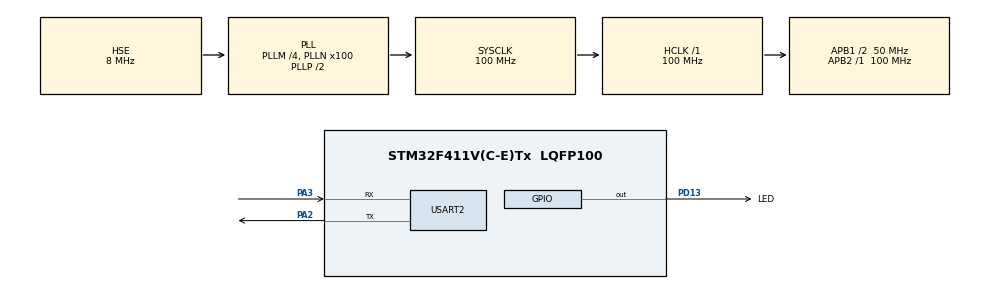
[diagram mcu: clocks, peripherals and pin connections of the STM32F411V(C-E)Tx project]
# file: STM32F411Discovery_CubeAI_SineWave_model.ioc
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Mcu.Family=STM32F4
Mcu.Name=STM32F411V(C-E)Tx
Mcu.Package=LQFP100
NVIC.PriorityGroup=NVIC_PRIORITYGROUP_4
PA13.Mode=Trace_Asynchronous_SW
PA13.Signal=SYS_JTMS-SWDIO
PA14.Mode=Trace_Asynchronous_SW
PA14.Signal=SYS_JTCK-SWCLK
PA2.Mode=Asynchronous
PA2.Signal=USART2_TX
PA3.Mode=Asynchronous
PA3.Signal=USART2_RX
PB3.Mode=Trace_Asynchronous_SW
PB3.Signal=SYS_JTDO-SWO
PD13.GPIO_Label=LED
PD13.Signal=GPIO_Output
PH0\ -\ OSC_IN.Mode=HSE-External-Oscillator
PH0\ -\ OSC_IN.Signal=RCC_OSC_IN
PH1\ -\ OSC_OUT.Mode=HSE-External-Oscillator
PH1\ -\ OSC_OUT.Signal=RCC_OSC_OUT
ProjectManager.HeapSize=0x200
ProjectManager.StackSize=0x400
ProjectManager.TargetToolchain=STM32CubeIDE
RCC.48MHZClocksFreq_Value=50000000
RCC.AHBFreq_Value=100000000
RCC.APB1CLKDivider=RCC_HCLK_DIV2
RCC.APB1Freq_Value=50000000
RCC.APB1TimFreq_Value=100000000
RCC.APB2Freq_Value=100000000
RCC.APB2TimFreq_Value=100000000
RCC.CortexFreq_Value=100000000
RCC.HCLKFreq_Value=100000000
RCC.HSE_VALUE=8000000
RCC.HSI_VALUE=16000000
RCC.LSE_VALUE=32768
RCC.PLLM=4
RCC.PLLN=100
RCC.PLLSourceVirtual=RCC_PLLSOURCE_HSE
RCC.SYSCLKFreq_VALUE=100000000
RCC.SYSCLKSource=RCC_SYSCLKSOURCE_PLLCLK
RCC.VCOOutputFreq_Value=200000000
STMicroelectronics.X-CUBE-AI.9.0.0.ActivationBufferSizeList=128
STMicroelectronics.X-CUBE-AI.9.0.0.ActivationBuffers=pool0
STMicroelectronics.X-CUBE-AI.9.0.0.ActivationNames=pool0
STMicroelectronics.X-CUBE-AI.9.0.0.ActivationSizes=AI_MYSINE_MODEL_DATA_ACTIVATION_1_SIZE
STMicroelectronics.X-CUBE-AI.9.0.0.HeapSize=0x800
STMicroelectronics.X-CUBE-AI.9.0.0.InternalRamActivationBufferMaxSize=AI_MYSINE_MODEL_DATA_ACTIVATIONS_SIZE
STMicroelectronics.X-CUBE-AI.9.0.0.LatestDirectoryUsed-0397be3772422ef14a2fe8161df3de680c5d4849b99f2a567ee8d7afe09b7841=C\:\\Users\\Bazar\\Desktop\\New folder
STMicroelectronics.X-CUBE-AI.9.0.0.MaximumNumberOfInputLayer=1
STMicroelectronics.X-CUBE-AI.9.0.0.MaximumNumberOfOutputLayer=1
STMicroelectronics.X-CUBE-AI.9.0.0.MaximumSizeOfInputLayer=1
STMicroelectronics.X-CUBE-AI.9.0.0.MaximumSizeOfOutputLayer=1
STMicroelectronics.X-CUBE-AI.9.0.0.ModelActualCompression-0397be3772422ef14a2fe8161df3de680c5d4849b99f2a567ee8d7afe09b7841=0.0
STMicroelectronics.X-CUBE-AI.9.0.0.ModelCompression-0397be3772422ef14a2fe8161df3de680c5d4849b99f2a567ee8d7afe09b7841=None
STMicroelectronics.X-CUBE-AI.9.0.0.ModelFlashOccupation-0397be3772422ef14a2fe8161df3de680c5d4849b99f2a567ee8d7afe09b7841=1284
STMicroelectronics.X-CUBE-AI.9.0.0.ModelHashList=0397be3772422ef14a2fe8161df3de680c5d4849b99f2a567ee8d7afe09b7841
STMicroelectronics.X-CUBE-AI.9.0.0.ModelKind-0397be3772422ef14a2fe8161df3de680c5d4849b99f2a567ee8d7afe09b7841=TFLITE
STMicroelectronics.X-CUBE-AI.9.0.0.ModelMacc-0397be3772422ef14a2fe8161df3de680c5d4849b99f2a567ee8d7afe09b7841=353
STMicroelectronics.X-CUBE-AI.9.0.0.ModelName-0397be3772422ef14a2fe8161df3de680c5d4849b99f2a567ee8d7afe09b7841=mysine_model
STMicroelectronics.X-CUBE-AI.9.0.0.ModelNameList=mysine_model
STMicroelectronics.X-CUBE-AI.9.0.0.ModelRamOccupation-0397be3772422ef14a2fe8161df3de680c5d4849b99f2a567ee8d7afe09b7841=128
STMicroelectronics.X-CUBE-AI.9.0.0.ModelStructureFile-0397be3772422ef14a2fe8161df3de680c5d4849b99f2a567ee8d7afe09b7841=C\:\\Users\\Bazar\\Desktop\\New folder\\sine_model.tflite
STMicroelectronics.X-CUBE-AI.9.0.0.ModelType-0397be3772422ef14a2fe8161df3de680c5d4849b99f2a567ee8d7afe09b7841=STM32Cube.AI MCU runtime
STMicroelectronics.X-CUBE-AI.9.0.0.ReadyForCodeGeneration=true
STMicroelectronics.X-CUBE-AI.9.0.0.StackSize=0x800
STMicroelectronics.X-CUBE-AI.9.0.0.WorkingBufferStartAddrList=0xFFFFFFFF
STMicroelectronics.X-CUBE-AI.9.0.0.XAaCUBEAaAICcArtificialOoIntelligenceJjCore=true
STMicroelectronics.X-CUBE-AI.9.0.0.copyWeightToRam=false
STMicroelectronics.X-CUBE-AI.9.0.0.customLayerConfigEnabled=false
STMicroelectronics.X-CUBE-AI.9.0.0.noOnnxIoTranspose=false
STMicroelectronics.X-CUBE-AI.9.0.0.useInputAllocation=true
STMicroelectronics.X-CUBE-AI.9.0.0.useOutputAllocation=true
USART2.VirtualMode=VM_ASYNC
VP_CRC_VS_CRC.Mode=CRC_Activate
VP_STMicroelectronics.X-CUBE-AI_VS_ArtificialOoIntelligenceJjXAaCUBEAaAI_9.0.0.Mode=ArtificialOoIntelligenceJjXAaCUBEAaAI
board=custom

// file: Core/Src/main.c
/* USER CODE BEGIN Header */
/**
  ******************************************************************************
  * @file           : main.c
  * @brief          : Main program body
  ******************************************************************************
  * @attention
  *
  * Copyright (c) 2025 STMicroelectronics.
  * All rights reserved.
  *
  * This software is licensed under terms that can be found in the LICENSE file
  * in the root directory of this software component.
  * If no LICENSE file comes with this software, it is provided AS-IS.
  *
  ******************************************************************************
  */
/* USER CODE END Header */
#include "main.h"

/* USER CODE BEGIN Includes */
#include "stdio.h"

#include "ai_datatypes_defines.h"
#include "ai_platform.h"
#include "mysine_model.h"
#include "mysine_model_data.h"
/* USER CODE END Includes */

CRC_HandleTypeDef hcrc;

UART_HandleTypeDef huart2;

/* USER CODE BEGIN PV */
AI_ALIGNED(4) ai_u8 in_data[AI_MYSINE_MODEL_IN_1_SIZE_BYTES];
AI_ALIGNED(4) ai_u8 out_data[AI_MYSINE_MODEL_OUT_1_SIZE_BYTES];

float y_val = 0;
/* USER CODE END PV */

void SystemClock_Config(void);
static void MX_GPIO_Init(void);
static void MX_CRC_Init(void);
static void MX_USART2_UART_Init(void);

/* USER CODE BEGIN 0 */
int _write(int file, char *ptr, int len)
{
	int i = 0;
	for(i = 0; i < len; i++)
	{
		ITM_SendChar(*ptr++);
	}
	return len;
}
/* USER CODE END 0 */

int main(void)
{

  /* MCU Configuration--------------------------------------------------------*/

  /* Reset of all peripherals, Initializes the Flash interface and the Systick. */
  HAL_Init();

  /* Configure the system clock */
  SystemClock_Config();

  /* Initialize all configured peripherals */
  MX_GPIO_Init();
  MX_CRC_Init();
  MX_USART2_UART_Init();
  /* USER CODE BEGIN 2 */
  printf("\r\n\r\nSTM32 X-Cube-AI test\r\n");

  // Chunk of memory used to hold intermediate values for neural network
  ai_u8 activations[AI_MYSINE_MODEL_DATA_ACTIVATIONS_SIZE];

  // Buffers used to store input and output tensors
  ai_buffer *ai_input;
  ai_buffer *ai_output;

  // Pointer to our model
  ai_handle sine_model = AI_HANDLE_NULL;

  ai_error err;
  ai_network_report report;

  // Initialize network
  // Create instance of neural network
  const ai_handle acts[] = { activations };

  err = ai_mysine_model_create_and_init(&sine_model, acts, NULL);
  if(err.type != AI_ERROR_NONE)
  {
	  printf("Error: could not create NN instance\r\n");
  }
  else
  {
	  printf("success in create NN instance\r\n");
  }

  // {optional} for debug/log purpose
  if(ai_mysine_model_get_report(sine_model, &report) != true)
  {
	  printf("ai get report error\r\n");
  }

  printf("Model name      : ");
  printf(report.model_name);
  printf("\nModel signature : ");
  printf(report.model_signature);

  ai_input = &report.inputs[0];
  ai_output = &report.outputs[0];
  printf("input[0] : (%d, %d, %d)\n", AI_BUFFER_SHAPE_ELEM(ai_input, AI_SHAPE_HEIGHT),
                                      AI_BUFFER_SHAPE_ELEM(ai_input, AI_SHAPE_WIDTH),
                                      AI_BUFFER_SHAPE_ELEM(ai_input, AI_SHAPE_CHANNEL));
  printf("output[0] : (%d, %d, %d)\n", AI_BUFFER_SHAPE_ELEM(ai_output, AI_SHAPE_HEIGHT),
                                       AI_BUFFER_SHAPE_ELEM(ai_output, AI_SHAPE_WIDTH),
                                       AI_BUFFER_SHAPE_ELEM(ai_output, AI_SHAPE_CHANNEL));

  // link inputs and outputs to the model
  ai_input[0].data = AI_HANDLE_PTR(in_data);
  ai_output[0].data = AI_HANDLE_PTR(out_data);

  ai_i32 nbatch;

  /* USER CODE END 2 */

  /* Infinite loop */
  while (1)
  {

    /* USER CODE BEGIN 3 */

	// Perform the inference
	float x = 0.0f;

	for(int i = 0 ; i < 60; i++)
	{
		x = x + 0.1;

		for(uint32_t i = 0; i < AI_MYSINE_MODEL_IN_1_SIZE; i++)
		{
			((ai_float *)in_data)[i] = (ai_float)x;
		}

		nbatch = ai_mysine_model_run(sine_model, &ai_input[0], &ai_output[0]);
		if(nbatch != 1)
		{
			printf("Error: could not run inference\r\n");
		}

		y_val = ((float *)out_data)[0];

		printf("%f \r\n", y_val);

		HAL_Delay(50);

		HAL_GPIO_TogglePin(LED_GPIO_Port, LED_Pin);
	}
	while(1);
  }
  /* USER CODE END 3 */
}

void SystemClock_Config(void)
{
  RCC_OscInitTypeDef RCC_OscInitStruct = {0};
  RCC_ClkInitTypeDef RCC_ClkInitStruct = {0};

  /** Configure the main internal regulator output voltage
  */
  __HAL_RCC_PWR_CLK_ENABLE();
  __HAL_PWR_VOLTAGESCALING_CONFIG(PWR_REGULATOR_VOLTAGE_SCALE1);

  /** Initializes the RCC Oscillators according to the specified parameters
  * in the RCC_OscInitTypeDef structure.
  */
  RCC_OscInitStruct.OscillatorType = RCC_OSCILLATORTYPE_HSE;
  RCC_OscInitStruct.HSEState = RCC_HSE_ON;
  RCC_OscInitStruct.PLL.PLLState = RCC_PLL_ON;
  RCC_OscInitStruct.PLL.PLLSource = RCC_PLLSOURCE_HSE;
  RCC_OscInitStruct.PLL.PLLM = 4;
  RCC_OscInitStruct.PLL.PLLN = 100;
  RCC_OscInitStruct.PLL.PLLP = RCC_PLLP_DIV2;
  RCC_OscInitStruct.PLL.PLLQ = 4;
  if (HAL_RCC_OscConfig(&RCC_OscInitStruct) != HAL_OK)
  {
    Error_Handler();
  }

  /** Initializes the CPU, AHB and APB buses clocks
  */
  RCC_ClkInitStruct.ClockType = RCC_CLOCKTYPE_HCLK|RCC_CLOCKTYPE_SYSCLK
                              |RCC_CLOCKTYPE_PCLK1|RCC_CLOCKTYPE_PCLK2;
  RCC_ClkInitStruct.SYSCLKSource = RCC_SYSCLKSOURCE_PLLCLK;
  RCC_ClkInitStruct.AHBCLKDivider = RCC_SYSCLK_DIV1;
  RCC_ClkInitStruct.APB1CLKDivider = RCC_HCLK_DIV2;
  RCC_ClkInitStruct.APB2CLKDivider = RCC_HCLK_DIV1;

  if (HAL_RCC_ClockConfig(&RCC_ClkInitStruct, FLASH_LATENCY_3) != HAL_OK)
  {
    Error_Handler();
  }
}

static void MX_CRC_Init(void)
{

  hcrc.Instance = CRC;
  if (HAL_CRC_Init(&hcrc) != HAL_OK)
  {
    Error_Handler();
  }

}

static void MX_USART2_UART_Init(void)
{

  huart2.Instance = USART2;
  huart2.Init.BaudRate = 115200;
  huart2.Init.WordLength = UART_WORDLENGTH_8B;
  huart2.Init.StopBits = UART_STOPBITS_1;
  huart2.Init.Parity = UART_PARITY_NONE;
  huart2.Init.Mode = UART_MODE_TX_RX;
  huart2.Init.HwFlowCtl = UART_HWCONTROL_NONE;
  huart2.Init.OverSampling = UART_OVERSAMPLING_16;
  if (HAL_UART_Init(&huart2) != HAL_OK)
  {
    Error_Handler();
  }

}

static void MX_GPIO_Init(void)
{
  GPIO_InitTypeDef GPIO_InitStruct = {0};

  /* GPIO Ports Clock Enable */
  __HAL_RCC_GPIOH_CLK_ENABLE();
  __HAL_RCC_GPIOA_CLK_ENABLE();
  __HAL_RCC_GPIOD_CLK_ENABLE();
  __HAL_RCC_GPIOB_CLK_ENABLE();

  /*Configure GPIO pin Output Level */
  HAL_GPIO_WritePin(LED_GPIO_Port, LED_Pin, GPIO_PIN_RESET);

  /*Configure GPIO pin : LED_Pin */
  GPIO_InitStruct.Pin = LED_Pin;
  GPIO_InitStruct.Mode = GPIO_MODE_OUTPUT_PP;
  GPIO_InitStruct.Pull = GPIO_NOPULL;
  GPIO_InitStruct.Speed = GPIO_SPEED_FREQ_LOW;
  HAL_GPIO_Init(LED_GPIO_Port, &GPIO_InitStruct);

}

void Error_Handler(void)
{
  __disable_irq();
  while (1)
  {
  }
}
